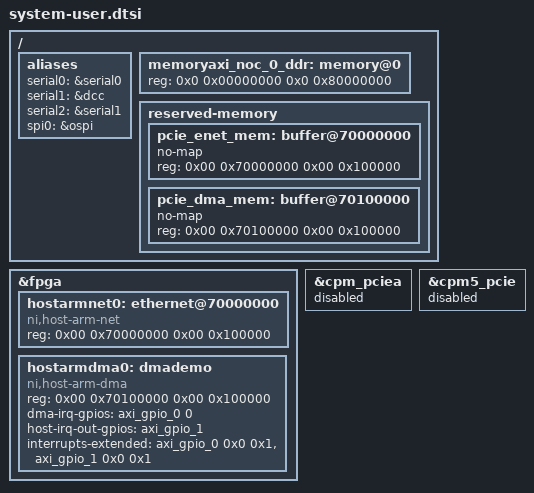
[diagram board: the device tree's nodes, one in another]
/ {
	aliases {
		serial0 = &serial0;
		serial1 = &dcc;
		serial2 = &serial1;
		spi0 = &ospi;
	};

	memoryaxi_noc_0_ddr: memory@0 {
		device_type = "memory";
		reg = <0x0 0x00000000 0x0 0x80000000>;
	};

	reserved-memory {
		#address-cells = <2>;
		#size-cells = <2>;
		ranges;

		pcie_enet_mem: buffer@70000000 {
			no-map;
			reg = <0x00 0x70000000 0x00 0x100000>;
		};
		pcie_dma_mem: buffer@70100000 {
			no-map;
			reg = <0x00 0x70100000 0x00 0x100000>;
		};
	};


};

&fpga {
	hostarmnet0: ethernet@70000000 {
		compatible = "ni,host-arm-net";
		reg = <0x00 0x70000000 0x00 0x100000>;

		status = "okay";
	};

	hostarmdma0: dmademo {
		compatible = "ni,host-arm-dma";
		reg = <0x00 0x70100000 0x00 0x100000>;
		dma-irq-gpios = <&axi_gpio_0 0 0>;
		host-irq-out-gpios = <&axi_gpio_1>;

		interrupts-extended = <&axi_gpio_0 0x0 0x1>, <&axi_gpio_1 0x0 0x1>;

		status = "okay";
	};

};

&cpm_pciea {
    status = "disabled";
};
&cpm5_pcie {
    status = "disabled";
};
